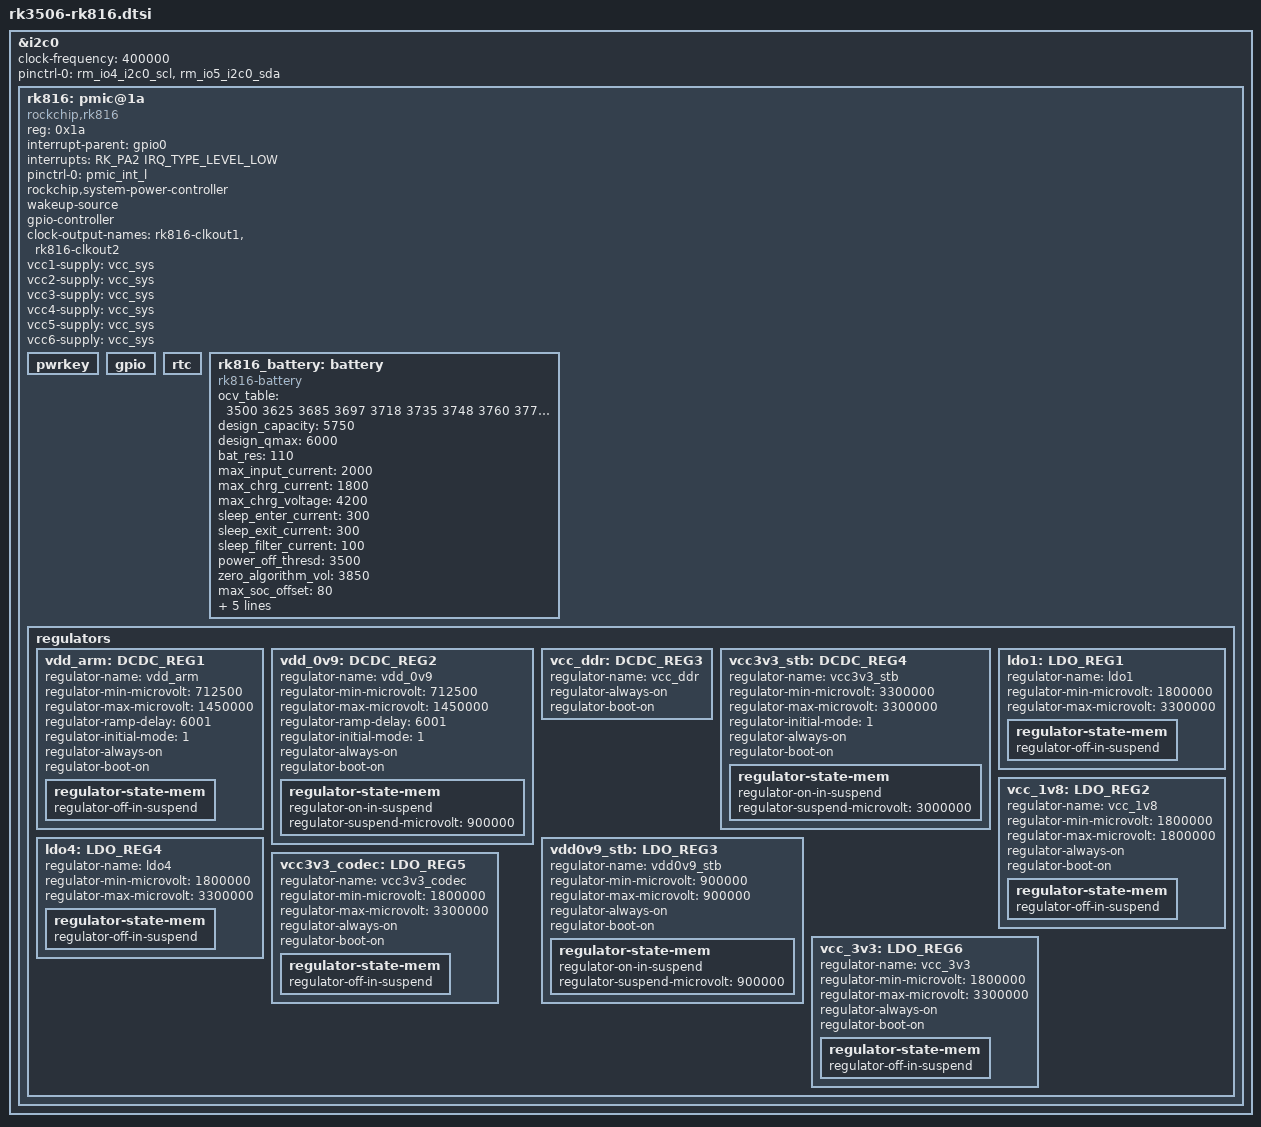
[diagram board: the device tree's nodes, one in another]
// SPDX-License-Identifier: (GPL-2.0+ OR MIT)
/*
 * Copyright (c) 2025 Rockchip Electronics Co., Ltd.
 *
 */

#include <dt-bindings/gpio/gpio.h>
#include <dt-bindings/pinctrl/rockchip.h>

&i2c0 {
	status = "okay";
	clock-frequency = <400000>;
	pinctrl-names = "default";
	pinctrl-0 = <&rm_io4_i2c0_scl &rm_io5_i2c0_sda>;

	rk816: pmic@1a {
		status = "okay";
		compatible = "rockchip,rk816";
		reg = <0x1a>;
		interrupt-parent = <&gpio0>;
		interrupts = <RK_PA2 IRQ_TYPE_LEVEL_LOW>;
		pinctrl-names = "default";
		pinctrl-0 = <&pmic_int_l>;
		rockchip,system-power-controller;
		wakeup-source;
		gpio-controller;
		#gpio-cells = <2>;
		#clock-cells = <1>;
		clock-output-names = "rk816-clkout1", "rk816-clkout2";

		vcc1-supply = <&vcc_sys>;
		vcc2-supply = <&vcc_sys>;
		vcc3-supply = <&vcc_sys>;
		vcc4-supply = <&vcc_sys>;
		vcc5-supply = <&vcc_sys>;
		vcc6-supply = <&vcc_sys>;

		pwrkey {
			status = "okay";
		};

		gpio {
			status = "okay";
		};

		rtc {
			status = "okay";
		};

		rk816_battery: battery {
			compatible = "rk816-battery";
			ocv_table = <3500 3625 3685 3697 3718 3735 3748
				     3760 3774 3788 3802 3816 3834 3853
				     3877 3908 3946 3975 4018 4071 4106>;
			design_capacity = <5750>;
			design_qmax = <6000>;
			bat_res = <110>;
			max_input_current = <2000>;
			max_chrg_current = <1800>;
			max_chrg_voltage = <4200>;
			sleep_enter_current = <300>;
			sleep_exit_current = <300>;
			sleep_filter_current = <100>;
			power_off_thresd = <3500>;
			zero_algorithm_vol = <3850>;
			max_soc_offset = <80>;
			monitor_sec = <5>;
			virtual_power = <0>;
			power_dc2otg = <0>;
			dc_det_adc = <0>;
			extcon = <&usb2phy>;
		};

		regulators {
			vdd_arm: DCDC_REG1{
				regulator-name = "vdd_arm";
				regulator-min-microvolt = <712500>;
				regulator-max-microvolt = <1450000>;
				regulator-ramp-delay = <6001>;
				regulator-initial-mode = <1>;
				regulator-always-on;
				regulator-boot-on;
				regulator-state-mem {
					regulator-off-in-suspend;
				};
			};

			vdd_0v9: DCDC_REG2 {
				regulator-name = "vdd_0v9";
				regulator-min-microvolt = <712500>;
				regulator-max-microvolt = <1450000>;
				regulator-ramp-delay = <6001>;
				regulator-initial-mode = <1>;
				regulator-always-on;
				regulator-boot-on;
				regulator-state-mem {
					regulator-on-in-suspend;
					regulator-suspend-microvolt = <900000>;
				};
			};

			vcc_ddr: DCDC_REG3 {
				regulator-name = "vcc_ddr";
				regulator-always-on;
				regulator-boot-on;
			};

			vcc3v3_stb: DCDC_REG4 {
				regulator-name = "vcc3v3_stb";
				regulator-min-microvolt = <3300000>;
				regulator-max-microvolt = <3300000>;
				regulator-initial-mode = <1>;
				regulator-always-on;
				regulator-boot-on;
				regulator-state-mem {
					regulator-on-in-suspend;
					regulator-suspend-microvolt = <3000000>;
				};
			};

			ldo1: LDO_REG1 {
				regulator-name = "ldo1";
				regulator-min-microvolt = <1800000>;
				regulator-max-microvolt = <3300000>;
				regulator-state-mem {
					regulator-off-in-suspend;
				};
			};

			vcc_1v8: LDO_REG2 {
				regulator-name = "vcc_1v8";
				regulator-min-microvolt = <1800000>;
				regulator-max-microvolt = <1800000>;
				regulator-always-on;
				regulator-boot-on;
				regulator-state-mem {
					regulator-off-in-suspend;
				};
			};

			vdd0v9_stb: LDO_REG3 {
				regulator-name = "vdd0v9_stb";
				regulator-min-microvolt = <900000>;
				regulator-max-microvolt = <900000>;
				regulator-always-on;
				regulator-boot-on;
				regulator-state-mem {
					regulator-on-in-suspend;
					regulator-suspend-microvolt = <900000>;
				};
			};

			ldo4: LDO_REG4 {
				regulator-name = "ldo4";
				regulator-min-microvolt = <1800000>;
				regulator-max-microvolt = <3300000>;
				regulator-state-mem {
					regulator-off-in-suspend;
				};
			};

			vcc3v3_codec: LDO_REG5 {
				regulator-name = "vcc3v3_codec";
				regulator-min-microvolt = <1800000>;
				regulator-max-microvolt = <3300000>;
				regulator-always-on;
				regulator-boot-on;
				regulator-state-mem {
					regulator-off-in-suspend;
				};
			};

			vcc_3v3: LDO_REG6 {
				regulator-name = "vcc_3v3";
				regulator-min-microvolt = <1800000>;
				regulator-max-microvolt = <3300000>;
				regulator-always-on;
				regulator-boot-on;
				regulator-state-mem {
					regulator-off-in-suspend;
				};
			};
		};
	};
};
